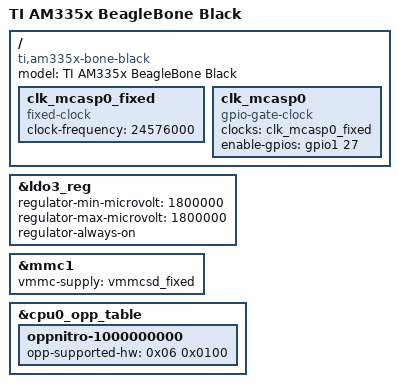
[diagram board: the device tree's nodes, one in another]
// SPDX-License-Identifier: GPL-2.0-only
/*
 * Copyright (C) 2012 Texas Instruments Incorporated - https://www.ti.com/
 */
/dts-v1/;

#include "am33xx.dtsi"
#include "am335x-bone-common.dtsi"

/ {
	model = "TI AM335x BeagleBone Black";
	compatible = "ti,am335x-bone-black", "ti,am335x-bone", "ti,am33xx";

	clk_mcasp0_fixed: clk_mcasp0_fixed {
	      #clock-cells = <0>;
	      compatible = "fixed-clock";
	      clock-frequency = <24576000>;
	};

	clk_mcasp0: clk_mcasp0 {
	      #clock-cells = <0>;
	      compatible = "gpio-gate-clock";
	      clocks = <&clk_mcasp0_fixed>;
	      enable-gpios = <&gpio1 27 GPIO_ACTIVE_HIGH>; /* BeagleBone Black Clk enable on GPIO1_27 */
	};
};

&ldo3_reg {
	regulator-min-microvolt = <1800000>;
	regulator-max-microvolt = <1800000>;
	regulator-always-on;
};

&mmc1 {
	vmmc-supply = <&vmmcsd_fixed>;
};

&cpu0_opp_table {
	/*
	 * All PG 2.0 silicon may not support 1GHz but some of the early
	 * BeagleBone Blacks have PG 2.0 silicon which is guaranteed
	 * to support 1GHz OPP so enable it for PG 2.0 on this board.
	 */
	oppnitro-1000000000 {
		opp-supported-hw = <0x06 0x0100>;
	};
};
